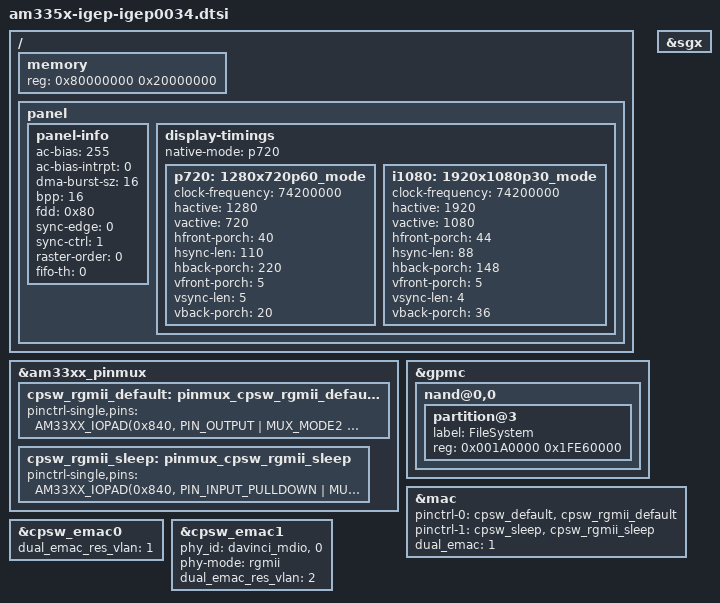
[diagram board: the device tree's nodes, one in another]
/*
 * am335x-igep-igep0034.dtsi - Device Tree addon file for IGEP0034 (Full)
 * MODULE based on AM3354. Depends on am335x-igep-igep0034-lite.dtsi.
 *
 * Copyright (C) 2016 ISEE 2007 SL - http://www.isee.biz
 *
 * This program is free software; you can redistribute it and/or modify
 * it under the terms of the GNU General Public License version 2 as
 * published by the Free Software Foundation.
 */

#include "am335x-igep-igep0034-lite.dtsi"

/ {
	memory {
		device_type = "memory";
		reg = <0x80000000 0x20000000>; /* 512 MB */
	};

	panel {
		status = "okay";

		panel-info {
			ac-bias           = <255>;
			ac-bias-intrpt    = <0>;
			dma-burst-sz      = <16>;
			bpp               = <16>;
			fdd               = <0x80>;
			sync-edge         = <0>;
			sync-ctrl         = <1>;
			raster-order      = <0>;
			fifo-th           = <0>;
		};

		display-timings {
			native-mode = <&p720>;
			p720: 1280x720p60_mode {
				clock-frequency = <74200000>;
				hactive = <1280>;
				vactive = <720>;
				hfront-porch = <40>;
				hsync-len = <110>;
				hback-porch = <220>;
				vfront-porch = <5>;
				vsync-len = <5>;
				vback-porch = <20>;
			};

			i1080: 1920x1080p30_mode {
				clock-frequency = <74200000>;
				hactive = <1920>;
				vactive = <1080>;
				hfront-porch = <44>;
				hsync-len = <88>;
				hback-porch = <148>;
				vfront-porch = <5>;
				vsync-len = <4>;
				vback-porch = <36>;
			};
		};
	};
};

&am33xx_pinmux {
	cpsw_rgmii_default: pinmux_cpsw_rgmii_default {
		pinctrl-single,pins = <
			/* Slave 2: eth1 device*/
			AM33XX_IOPAD(0x840, PIN_OUTPUT | MUX_MODE2 ) /* gpmc_a0.rgmii2_tctl */
			AM33XX_IOPAD(0x844, PIN_INPUT | MUX_MODE2 ) /* gpmc_a1.rgmii2_rctl */
			AM33XX_IOPAD(0x858, PIN_OUTPUT | MUX_MODE2 ) /* gpmc_a6.rgmii2_tclk */
			AM33XX_IOPAD(0x85C, PIN_INPUT | MUX_MODE2 ) /* gpmc_a7.rgmii2_rclk */
			AM33XX_IOPAD(0x854, PIN_OUTPUT | MUX_MODE2 ) /* gpmc_a5.rgmii2_td0 */
			AM33XX_IOPAD(0x850, PIN_OUTPUT | MUX_MODE2 ) /* gpmc_a4.rgmii2_td1 */
			AM33XX_IOPAD(0x84C, PIN_OUTPUT | MUX_MODE2 ) /* gpmc_a3.rgmii2_td2 */
			AM33XX_IOPAD(0x848, PIN_OUTPUT | MUX_MODE2 ) /* gpmc_a2.rgmii2_td3 */
			AM33XX_IOPAD(0x86C, PIN_INPUT | MUX_MODE2 ) /* gpmc_a11.rgmii2_rd0 */
			AM33XX_IOPAD(0x868, PIN_INPUT | MUX_MODE2 ) /* gpmc_a10.rgmii2_rd1 */
			AM33XX_IOPAD(0x864, PIN_INPUT | MUX_MODE2 ) /* gpmc_a9.rgmii2_rd2 */
			AM33XX_IOPAD(0x860, PIN_INPUT | MUX_MODE2 ) /* gpmc_a8.rgmii2_rd3 */
		>;
	};

	cpsw_rgmii_sleep: pinmux_cpsw_rgmii_sleep {
		pinctrl-single,pins = <
			/* Slave 2: eth1 device*/
			AM33XX_IOPAD(0x840, PIN_INPUT_PULLDOWN | MUX_MODE7)
			AM33XX_IOPAD(0x844, PIN_INPUT_PULLDOWN | MUX_MODE7)
			AM33XX_IOPAD(0x858, PIN_INPUT_PULLDOWN | MUX_MODE7)
			AM33XX_IOPAD(0x85C, PIN_INPUT_PULLDOWN | MUX_MODE7)
			AM33XX_IOPAD(0x854, PIN_INPUT_PULLDOWN | MUX_MODE7)
			AM33XX_IOPAD(0x850, PIN_INPUT_PULLDOWN | MUX_MODE7)
			AM33XX_IOPAD(0x84C, PIN_INPUT_PULLDOWN | MUX_MODE7)
			AM33XX_IOPAD(0x848, PIN_INPUT_PULLDOWN | MUX_MODE7)
			AM33XX_IOPAD(0x86C, PIN_INPUT_PULLDOWN | MUX_MODE7)
			AM33XX_IOPAD(0x868, PIN_INPUT_PULLDOWN | MUX_MODE7)
			AM33XX_IOPAD(0x864, PIN_INPUT_PULLDOWN | MUX_MODE7)
			AM33XX_IOPAD(0x860, PIN_INPUT_PULLDOWN | MUX_MODE7)
		>;
	};
};

&gpmc {
	ranges = <0 0 0x08000000 0x20000000>;	/* CS0: 512 MB for NAND */

	nand@0,0 {
		/* MTD partition table */
		partition@3 {
			label = "FileSystem";
			reg = <0x001A0000 0x1FE60000>;
		};
	};
};

&sgx {
	status = "okay";
};

&mac {
	pinctrl-0 = <&cpsw_default &cpsw_rgmii_default>;
	pinctrl-1 = <&cpsw_sleep &cpsw_rgmii_sleep>;
	dual_emac = <1>;
};

&cpsw_emac0 {
	dual_emac_res_vlan = <1>;
};

&cpsw_emac1 {
	phy_id = <&davinci_mdio>, <0>;
	phy-mode = "rgmii";
	dual_emac_res_vlan = <2>;
};
